# STM32F756 register map
File version: 1.9
CPU: CM7 r0p1, little endian, MPU, FPU, 4 interrupt priority bits
Registers are 32-bit, read-write, reset 0x0 unless marked. A register's access mark holds for its fields unless they carry their own. Offsets are from the block's base; [hi:lo] are bit positions; lines under a group give offsets from that group; {n}, {i} and the like mark numbered series.

## SPDIFRX — Receiver Interface
Base 0x40004000
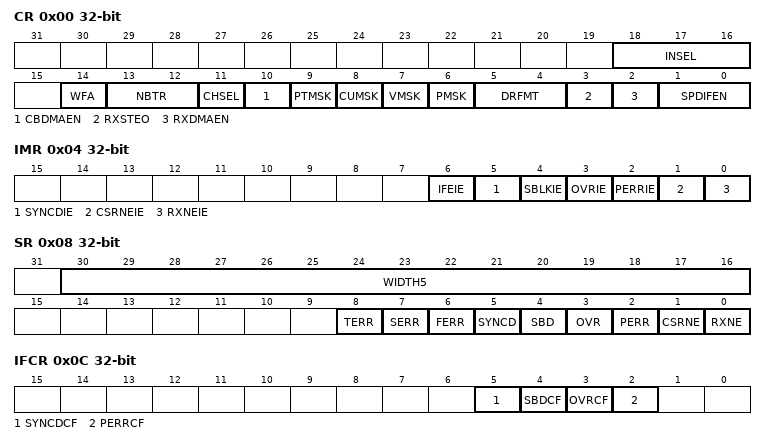
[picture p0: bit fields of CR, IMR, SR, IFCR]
0x00 CR — Control register
  [18:16] INSEL — input selection
  [14] WFA — Wait For Activity
  [13:12] NBTR — Maximum allowed re-tries during synchronization phase
  [11] CHSEL — Channel Selection
  [10] CBDMAEN — Control Buffer DMA ENable for control flow
  [9] PTMSK — Mask of Preamble Type bits
  [8] CUMSK — Mask of channel status and user bits
  [7] VMSK — Mask of Validity bit
  [6] PMSK — Mask Parity error bit
  [5:4] DRFMT — RX Data format
  [3] RXSTEO — STerEO Mode
  [2] RXDMAEN — Receiver DMA ENable for data flow
  [1:0] SPDIFEN — Peripheral Block Enable
0x04 IMR — Interrupt mask register
  [6] IFEIE — Serial Interface Error Interrupt Enable
  [5] SYNCDIE — Synchronization Done
  [4] SBLKIE — Synchronization Block Detected Interrupt Enable
  [3] OVRIE — Overrun error Interrupt Enable
  [2] PERRIE — Parity error interrupt enable
  [1] CSRNEIE — Control Buffer Ready Interrupt Enable
  [0] RXNEIE — RXNE interrupt enable
0x08 SR ro — Status register
  [30:16] WIDTH5 — Duration of 5 symbols counted with SPDIF_CLK
  [8] TERR — Time-out error
  [7] SERR — Synchronization error
  [6] FERR — Framing error
  [5] SYNCD — Synchronization Done
  [4] SBD — Synchronization Block Detected
  [3] OVR — Overrun error
  [2] PERR — Parity error
  [1] CSRNE — Control Buffer register is not empty
  [0] RXNE — Read data register not empty
0x0C IFCR wo — Interrupt Flag Clear register
  [5] SYNCDCF — Clears the Synchronization Done flag
  [4] SBDCF — Clears the Synchronization Block Detected flag
  [3] OVRCF — Clears the Overrun error flag
  [2] PERRCF — Clears the Parity error flag
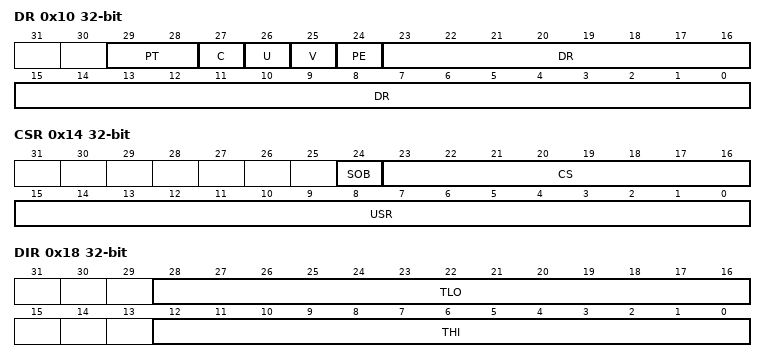
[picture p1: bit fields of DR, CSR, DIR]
0x10 DR ro — Data input register
  [29:28] PT — Preamble Type
  [27] C — Channel Status bit
  [26] U — User bit
  [25] V — Validity bit
  [24] PE — Parity Error bit
  [23:0] DR — Parity Error bit
0x14 CSR ro — Channel Status register
  [24] SOB — Start Of Block
  [23:16] CS — Channel A status information
  [15:0] USR — User data information
0x18 DIR ro — Debug Information register
  [28:16] TLO — Threshold LOW
  [12:0] THI — Threshold HIGH

## OTG_FS_HOST — USB on the go full speed
Base 0x50000400
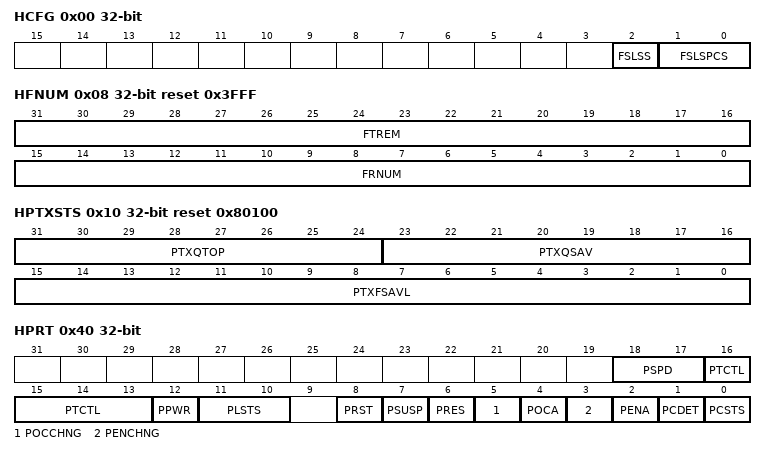
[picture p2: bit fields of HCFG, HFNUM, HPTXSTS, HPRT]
0x00 HCFG — OTG_FS host configuration register (OTG_FS_HCFG)
  [2] FSLSS — FS- and LS-only support
  [1:0] FSLSPCS — FS/LS PHY clock select
0x04 HFIR reset 0xEA60 — OTG_FS Host frame interval register
  [15:0] FRIVL — Frame interval
0x08 HFNUM ro reset 0x3FFF — OTG_FS host frame number/frame time remaining register (OTG_FS_HFNUM)
  [31:16] FTREM — Frame time remaining
  [15:0] FRNUM — Frame number
0x10 HPTXSTS access per field reset 0x80100 — OTG_FS_Host periodic transmit FIFO/queue status register (OTG_FS_HPTXSTS)
  [31:24] PTXQTOP ro — Top of the periodic transmit request queue
  [23:16] PTXQSAV ro — Periodic transmit request queue space available
  [15:0] PTXFSAVL rw — Periodic transmit data FIFO space available
0x14 HAINT ro — OTG_FS Host all channels interrupt register
  [15:0] HAINT — Channel interrupts
0x18 HAINTMSK — OTG_FS host all channels interrupt mask register
  [15:0] HAINTM — Channel interrupt mask
0x40 HPRT access per field — OTG_FS host port control and status register (OTG_FS_HPRT)
  [18:17] PSPD ro — Port speed
  [16:13] PTCTL rw — Port test control
  [12] PPWR rw — Port power
  [11:10] PLSTS ro — Port line status
  [8] PRST rw — Port reset
  [7] PSUSP rw — Port suspend
  [6] PRES rw — Port resume
  [5] POCCHNG rw — Port overcurrent change
  [4] POCA ro — Port overcurrent active
  [3] PENCHNG rw — Port enable/disable change
  [2] PENA rw — Port enable
  [1] PCDET rw — Port connect detected
  [0] PCSTS ro — Port connect status
{0x100+0x20*i} HC{i} (i=0..11) group — Host channel
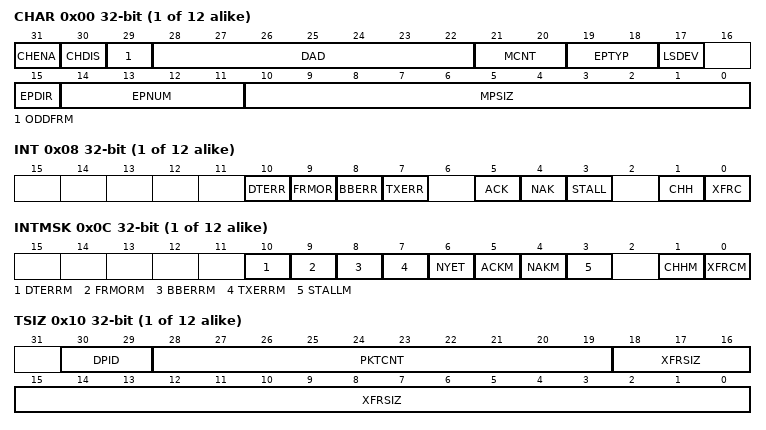
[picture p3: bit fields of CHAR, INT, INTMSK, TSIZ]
  0x00 CHAR — OTG_FS host channel-0 characteristics register (OTG_FS_HCCHAR0)
    [31] CHENA — Channel enable
    [30] CHDIS — Channel disable
    [29] ODDFRM — Odd frame
    [28:22] DAD — Device address
    [21:20] MCNT — Multicount
    [19:18] EPTYP — Endpoint type
    [17] LSDEV — Low-speed device
    [15] EPDIR — Endpoint direction
    [14:11] EPNUM — Endpoint number
    [10:0] MPSIZ — Maximum packet size
  0x08 INT — OTG_FS host channel-0 interrupt register (OTG_FS_HCINT0)
    [10] DTERR — Data toggle error
    [9] FRMOR — Frame overrun
    [8] BBERR — Babble error
    [7] TXERR — Transaction error
    [5] ACK — ACK response received/transmitted interrupt
    [4] NAK — NAK response received interrupt
    [3] STALL — STALL response received interrupt
    [1] CHH — Channel halted
    [0] XFRC — Transfer completed
  0x0C INTMSK — OTG_FS host channel-0 mask register (OTG_FS_HCINTMSK0)
    [10] DTERRM — Data toggle error mask
    [9] FRMORM — Frame overrun mask
    [8] BBERRM — Babble error mask
    [7] TXERRM — Transaction error mask
    [6] NYET — response received interrupt mask
    [5] ACKM — ACK response received/transmitted interrupt mask
    [4] NAKM — NAK response received interrupt mask
    [3] STALLM — STALL response received interrupt mask
    [1] CHHM — Channel halted mask
    [0] XFRCM — Transfer completed mask
  0x10 TSIZ — OTG_FS host channel-0 transfer size register
    [30:29] DPID — Data PID
    [28:19] PKTCNT — Packet count
    [18:0] XFRSIZ — Transfer size
